# Port_Mapping_Control_1 register map
Vendor: Texas Instruments
Peripheral module from a debugger description file (folder msp430).
Registers are 16-bit, access not given, no defined reset value unless marked. A register's access mark holds for its fields unless they carry their own. Offsets are as the file gives them; lines under a group give offsets from that group; [hi:lo] are bit positions; {n}, {i} and the like mark numbered series; 'fields as' and 'values as' point back to an identical list; <NAME> marks a mode.

## Port_Mapping_Control
0x1C0 PMAPKEYID — Port Mapping Key register
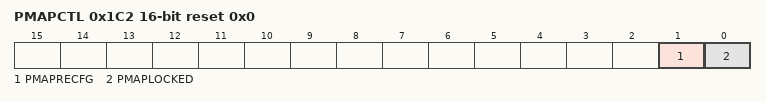
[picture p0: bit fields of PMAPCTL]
0x1C2 PMAPCTL rw reset 0x0 — Port Mapping control register
  [1] PMAPRECFG — Port Mapping re-configuration control bit
  [0] PMAPLOCKED — Port Mapping Lock bit. Read only
